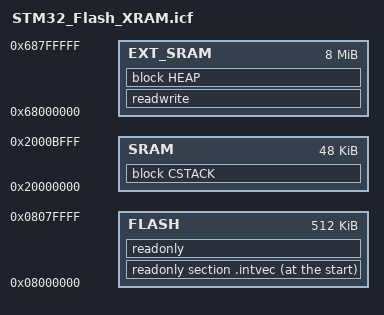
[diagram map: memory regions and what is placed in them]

//
// Define a memory region that covers the entire 4 GB addressible space of the
// processor.
//
define memory mem with size = 4G;

//
// Define a region for the on-chip flash.
//
define region FLASH = mem:[from 0x8000000 to 0x807FFFF];

//
// Define a region for the on-chip SRAM.
//
define region SRAM = mem:[from 0x20000000 to 0x2000BFFF];
define region EXT_SRAM = mem:[from 0x68000000 to 0x687FFFFF];

//
// Define a block for the heap.  The size should be set to something other
// than zero if things in the C library that require the heap are used.
//
define block HEAP with alignment = 8, size = 0x00000000 { };

define block CSTACK with alignment = 8, size = 0x00000400 { };

//
// Indicate that the read/write values should be initialized by copying from
// flash.
//
initialize by copy { readwrite };

//
// Initicate that the noinit values should be left alone.  This includes the
// stack, which if initialized will destroy the return address from the
// initialization code, causing the processor to branch to zero and fault.
//
do not initialize { section .noinit };

//
// Place the interrupt vectors at the start of flash.
//
place at start of FLASH { readonly section .intvec };

//
// Place the remainder of the read-only items into flash.
//
place in FLASH { readonly };

place in SRAM  {block CSTACK};

//
// Place all read/write items into EXT_SRAM.
//
place in EXT_SRAM { readwrite, block HEAP};
